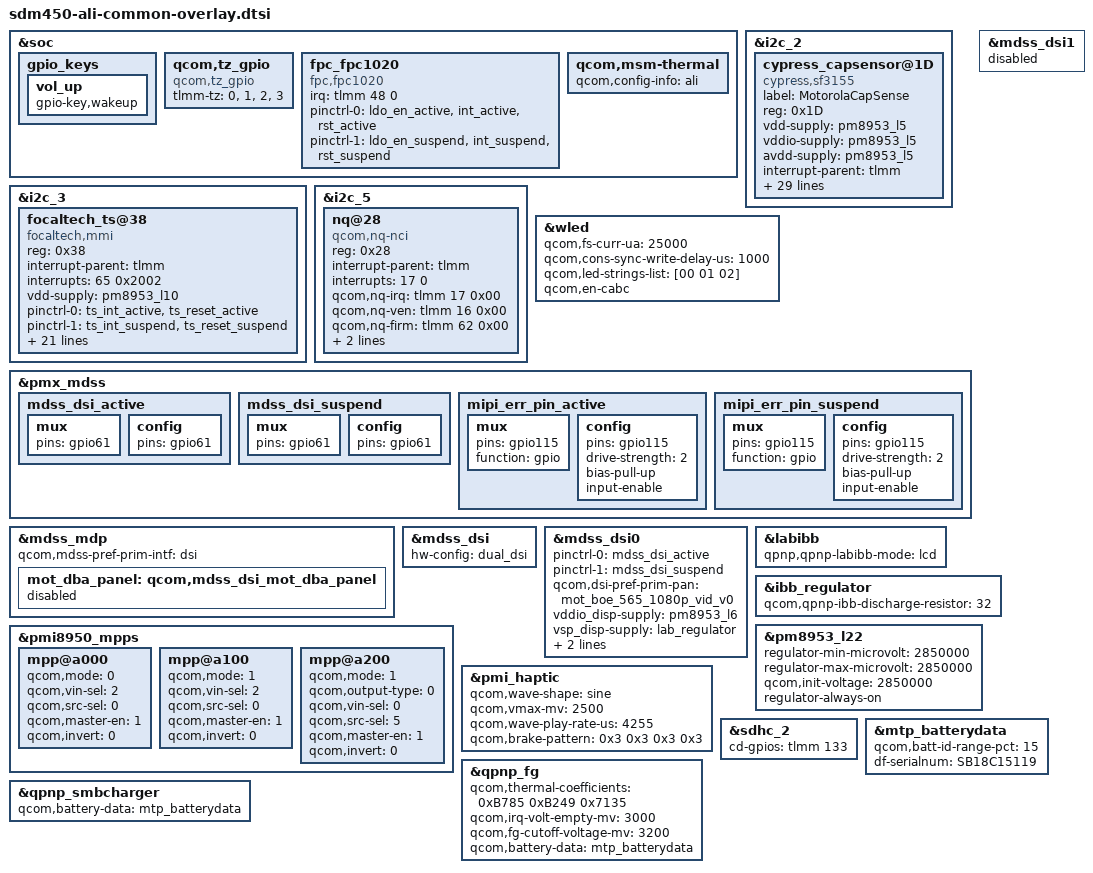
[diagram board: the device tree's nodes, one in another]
/*
 * Copyright (c) 2017-2018, The Linux Foundation. All rights reserved.
 *
 * This program is free software; you can redistribute it and/or modify
 * it under the terms of the GNU General Public License version 2 and
 * only version 2 as published by the Free Software Foundation.
 *
 * This program is distributed in the hope that it will be useful,
 * but WITHOUT ANY WARRANTY; without even the implied warranty of
 * MERCHANTABILITY or FITNESS FOR A PARTICULAR PURPOSE.  See the
 * GNU General Public License for more details.
 */

#include "sdm450-moto-common-overlay.dtsi"
#include "sdm450-ali-pinctrl-overlay.dtsi"
#include "sdm450-camera-sensor-mot-ali-overlay.dtsi"
#include "dsi-panel-mot-boe-565-1080p-vid.dtsi"
#include "dsi-panel-mot-tianma-565-1080p-vid.dtsi"
#include "dsi-panel-mot-auo-565-1080p-vid.dtsi"
#include "dsi-panel-mot-dummy-qhd-video.dtsi"
#include "sdm450-ali-audio-overlay.dtsi"

&soc {
	gpio_keys {
		vol_up {
			gpio-key,wakeup;
		};
	};

	qcom,tz_gpio {
		compatible = "qcom,tz_gpio";
		tlmm-tz = <0>,
			<1>,
			<2>,
			<3>;
	};
};

&i2c_2 { /* BLSP1 QUP2 */
	status = "okay";

	cypress_capsensor@1D {
		compatible = "cypress,sf3155";
		label = "MotorolaCapSense";
		reg = <0x1D>;
		vdd-supply = <&pm8953_l5>;
		vddio-supply = <&pm8953_l5>;
		avdd-supply = <&pm8953_l5>;
		interrupt-parent = <&tlmm>;
		interrupts = <86 0x2008>;
		silicon_id = <0x0BB11477>;
		block_size = <64>;
		num_of_blocks = <256>;
		secure_bytes = <32>;
		pinctrl-names = "default";
		gpios = <&tlmm 95 0>, /* RESET */
			<&tlmm 59 0>, /* programming SCLK */
			<&tlmm 140 0>, /* programming SDAT */
			<&tlmm 86 0x2008>;
		use-raw-gpio-rw = <1>;
		gpio_base_addr = <0x01000004>;
		gpio_base_size = <0x3d0900>;
		cyttsp,sar-status-reg = <0x50>;
		cyttsp,standby-reg = <0x51>;
		cyttsp,bootloader-addr = <0x02>;
		cyttsp,key-num = <4>;
		cyttsp,key-codes = <4>;
		threshold_reg_array_len = <16>;
		na_threshold_array_val = <0x3A 0x32 0x3B 0x00 0x3C 0x32 0x3D 0x00 0x3E 0x32
			0x3F 0x00 0x40 0x32 0x41 0x00 0x2A 0x90 0x2B 0x01
			0x2C 0x90 0x2D 0x01 0x2E 0x2C 0x2F 0x01 0x30 0x2C 0x31 0x01>;
		latam_threshold_array_val = <0x3A 0x32 0x3B 0x00 0x3C 0x32 0x3D 0x00 0x3E 0x32
			0x3F 0x00 0x40 0x32 0x41 0x00 0x2A 0x90 0x2B 0x01
			0x2C 0x90 0x2D 0x01 0x2E 0x2C 0x2F 0x01 0x30 0x2C 0x31 0x01>;
		emea_threshold_array_val = <0x3A 0x32 0x3B 0x00 0x3C 0x32 0x3D 0x00 0x3E 0x32
			0x3F 0x00 0x40 0x32 0x41 0x00 0x2A 0x90 0x2B 0x01
			0x2C 0x90 0x2D 0x01 0x2E 0x2C 0x2F 0x01 0x30 0x2C 0x31 0x01>;
		prc_threshold_array_val = <0x3A 0x32 0x3B 0x00 0x3C 0x32 0x3D 0x00 0x3E 0x32
			0x3F 0x00 0x40 0x32 0x41 0x00 0x2A 0x90 0x2B 0x01
			0x2C 0x90 0x2D 0x01 0x2E 0x2C 0x2F 0x01 0x30 0x2C 0x31 0x01>;
		apac_threshold_array_val = <0x3A 0x32 0x3B 0x00 0x3C 0x32 0x3D 0x00 0x3E 0x32
			0x3F 0x00 0x40 0x32 0x41 0x00 0x2A 0x90 0x2B 0x01
			0x2C 0x90 0x2D 0x01 0x2E 0x2C 0x2F 0x01 0x30 0x2C 0x31 0x01>;
		brazil_threshold_array_val = <0x3A 0x32 0x3B 0x00 0x3C 0x32 0x3D 0x00 0x3E 0x32
			0x3F 0x00 0x40 0x32 0x41 0x00 0x2A 0x90 0x2B 0x01
			0x2C 0x90 0x2D 0x01 0x2E 0x2C 0x2F 0x01 0x30 0x2C 0x31 0x01>;
		default_threshold_array_val = <0x3A 0x32 0x3B 0x00 0x3C 0x32 0x3D 0x00 0x3E 0x32
			0x3F 0x00 0x40 0x32 0x41 0x00 0x2A 0x90 0x2B 0x01
			0x2C 0x90 0x2D 0x01 0x2E 0x2C 0x2F 0x01 0x30 0x2C 0x31 0x01>;
	};
};

&i2c_3 { /* BLSP1 QUP3 */
	status = "okay";
	focaltech_ts@38 {
		compatible = "focaltech,mmi";
		reg = <0x38>;
		interrupt-parent = <&tlmm>;
		interrupts = <65 0x2002>;
		vdd-supply = <&pm8953_l10>;
		pinctrl-names = "pmx_ts_active", "pmx_ts_suspend";
		pinctrl-0 = <&ts_int_active &ts_reset_active>;
		pinctrl-1 = <&ts_int_suspend &ts_reset_suspend>;
		focaltech,name = "ft5446";
		focaltech,family-id = <0x54>;
		focaltech,reset-gpio = <&tlmm 64 0x00>;
		focaltech,irq-gpio = <&tlmm 65 0x2008>;
		focaltech,display-coords = <0 0 1080 2160>;
		focaltech,panel-coords = <0 0 1080 2160>;
		focaltech,i2c-pull-up;
		focaltech,group-id = <1>;
		focaltech,hard-reset-delay-ms = <20>;
		focaltech,soft-reset-delay-ms = <200>;
		focaltech,num-max-touches = <10>;
		focaltech,fw-delay-aa-ms = <2>;
		focaltech,fw-delay-55-ms = <2>;
		focaltech,fw-upgrade-id1 = <0x54>;
		focaltech,fw-upgrade-id2 = <0x22>;
		focaltech,fw-delay-readid-ms = <20>;
		focaltech,fw-delay-era-flsh-ms = <2000>;
		focaltech,resume-in-workqueue;
		focaltech,ignore-id-check;
		focaltech,vendor_ids = <0x01 0x02 0x04>;
		focaltech,vendor_names ="ofilm", "toptouch", "biel";
	};
};

&i2c_5 { /* BLSP2 QUP1 (NFC) */
	nq@28 {/* NFC PN553 */
		compatible = "qcom,nq-nci";
		reg = <0x28>;
		interrupt-parent = <&tlmm>;
		interrupts = <17 0>;
		interrupt-names = "nfc_irq";
		qcom,nq-irq = <&tlmm 17 0x00>;
		qcom,nq-ven = <&tlmm 16 0x00>;
		qcom,nq-firm = <&tlmm 62 0x00>;
		pinctrl-names = "default";
		pinctrl-0 = <&nfc_irq_default &nfc_ven_default
				&nfc_firm_default>;
	};
};

&wled {
	qcom,fs-curr-ua = <25000>;
	qcom,cons-sync-write-delay-us = <1000>;
	qcom,led-strings-list = [00 01 02];
	qcom,en-cabc;
};

&pmx_mdss {
	mdss_dsi_active {
		mux {
			pins = "gpio61";
		};

		config {
			pins = "gpio61";
		};
	};

	mdss_dsi_suspend {
		mux {
			pins = "gpio61";
		};

		config {
			pins = "gpio61";
		};
	};

	mipi_err_pin_active: mipi_err_pin_active {
		mux {
			pins = "gpio115";
			function = "gpio";
		};

		config {
			pins = "gpio115";
			drive-strength = <2>; /* 2 mA */
			bias-pull-up; /* pull up */
			input-enable;
		};
	};

	mipi_err_pin_suspend: mipi_err_pin_suspend {
		mux {
			pins = "gpio115";
			function = "gpio";
		};

		config {
			pins = "gpio115";
			drive-strength = <2>; /* 2 mA */
			bias-pull-up; /* pull up */
			input-enable;
		};
	};
};

&mdss_mdp {
	qcom,mdss-pref-prim-intf = "dsi";

	mot_dba_panel: qcom,mdss_dsi_mot_dba_panel{
		#include "dsi-panel-mot-mod-fwvga-video-common.dtsi"
	};
};

&mdss_dsi {
	hw-config = "dual_dsi";
};

&mdss_dsi0 {
	pinctrl-names = "mdss_default", "mdss_sleep";
	pinctrl-0 = <&mdss_dsi_active>;
	pinctrl-1 = <&mdss_dsi_suspend>;

	qcom,dsi-pref-prim-pan = <&mot_boe_565_1080p_vid_v0>;

	vddio_disp-supply = <&pm8953_l6>;
	vsp_disp-supply = <&lab_regulator>;
	vsn_disp-supply = <&ibb_regulator>;

	qcom,platform-reset-gpio = <&tlmm 61 0>;
};

&mdss_dsi1 {
	status = "disabled";
};

&mot_dba_panel {
	status = "disabled";
};


/* display boost and inverting boost regulators */
&labibb {
	status = "ok";
	qpnp,qpnp-labibb-mode = "lcd";
};

&ibb_regulator {
	qcom,qpnp-ibb-discharge-resistor = <32>;
};

&pmi8950_mpps {
	mpp@a000 { /* MPP 1 - MOD_BP_OC_FAULT_N */
		qcom,mode = <0>;	/* Input */
		qcom,vin-sel = <2>;	/* 1.8 */
		qcom,src-sel = <0>;	/* GPIO */
		qcom,master-en = <1>;	/* Enable GPIO */
		qcom,invert = <0>;	/* Output low */
		status = "okay";
	};
	mpp@a100 { /* MPP 2 - MOD_F_FLASH */
		qcom,mode = <1>;	/* Digital output */
		qcom,vin-sel = <2>;	/* 1.8 */
		qcom,src-sel = <0>;	/* GPIO */
		qcom,master-en = <1>;	/* Enable GPIO */
		qcom,invert = <0>;	/* Output low */
		status = "okay";
	};
	mpp@a200 { /* MPP 3 - DISP_AVDD_SHUTDOWN */
		qcom,mode = <1>;		/* Digital output */
		qcom,output-type = <0>;		/* CMOS logic */
		qcom,vin-sel = <0>;
		qcom,src-sel = <5>;		/* DTEST2 */
		qcom,master-en = <1>;		/* Enable GPIO */
		qcom,invert = <0>;
		status = "okay";
	};
};

&pm8953_l22 {
	regulator-min-microvolt = <2850000>;
	regulator-max-microvolt = <2850000>;
	qcom,init-voltage = <2850000>;
	regulator-always-on;
};

&soc {
	fpc_fpc1020{
		compatible = "fpc,fpc1020";
		status = "ok";
		irq = <&tlmm 48 0>;

		pinctrl-names = "default", "suspend";
		pinctrl-0 = <&ldo_en_active &int_active &rst_active>;
		pinctrl-1 = <&ldo_en_suspend &int_suspend &rst_suspend>;
	};
	qcom,msm-thermal {
		qcom,config-info = "ali";
	};
};

&pmi_haptic{
	qcom,wave-shape = "sine";
	qcom,vmax-mv = <2500>;
	qcom,wave-play-rate-us = <4255>;
	qcom,brake-pattern = <0x3 0x3 0x3 0x3>;
};

&sdhc_2 {
	cd-gpios = <&tlmm 133 0x0>;
};

&mtp_batterydata {
	qcom,batt-id-range-pct = <15>;
	df-serialnum = "SB18C15119";
	#include "batterydata-hg30-atl-ali.dtsi"
	#include "batterydata-hg30-scud.dtsi"
	#include "batterydata-hg30-epcos.dtsi"
};

&qpnp_fg {
	qcom,thermal-coefficients =  /bits/ 16 <0xB785 0xB249 0x7135>;
	qcom,irq-volt-empty-mv = <3000>;
	qcom,fg-cutoff-voltage-mv = <3200>;
	qcom,battery-data = <&mtp_batterydata>;
};

&qpnp_smbcharger {
	qcom,battery-data = <&mtp_batterydata>;
};
